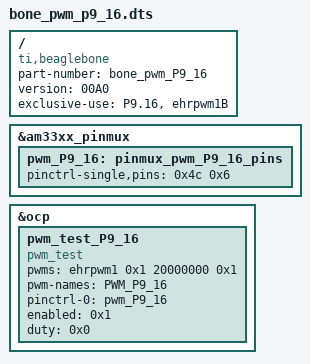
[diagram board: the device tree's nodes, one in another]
/dts-v1/;

/ {
	compatible = "ti,beaglebone", "ti,beaglebone-black";
	part-number = "bone_pwm_P9_16";
	version = "00A0";
	exclusive-use = "P9.16", "ehrpwm1B";

	fragment@0 {
		target = <&am33xx_pinmux>;

		__overlay__ {

			pwm_P9_16:pinmux_pwm_P9_16_pins {
				pinctrl-single,pins = <0x4c 0x6>;
				linux,phandle = <0x1>;
				phandle = <0x1>;
			};
		};
	};

	fragment@1 {
		target = <&ocp>;

		__overlay__ {

			pwm_test_P9_16 {
				compatible = "pwm_test";
				pwms = <&ehrpwm1 0x1 20000000 0x1>;
				pwm-names = "PWM_P9_16";
				pinctrl-names = "default";
				pinctrl-0 = <&pwm_P9_16>;
				enabled = <0x1>;
				duty = <0x0>;
				status = "okay";
			};
		};
	};

	__symbols__ {
		pwm_P9_16 = "/fragment@0/__overlay__/pinmux_pwm_P9_16_pins";
	};

	__fixups__ {
		am33xx_pinmux = "/fragment@0:target:0";
		ocp = "/fragment@1:target:0";
		ehrpwm1 = "/fragment@1/__overlay__/pwm_test_P9_16:pwms:0";
	};

	__local_fixups__ {
		fixup = "/fragment@1/__overlay__/pwm_test_P9_16:pinctrl-0:0";
	};
};
